# moondancer register map
Vendor: luna-soc
Registers are 8-bit, read-write, reset 0x0 unless marked. A register's access mark holds for its fields unless they carry their own. Offsets are from the block's base; [hi:lo] are bit positions; <NAME> marks a mode.

## timer0
Base 0xF0000500
Same registers: timer1 0xF0000600
0x00 enable — Counter enable
  [0] enable
0x01 mode — Timer mode. When ``periodic`` is set to 1 the counter will automatically be reset to the reload value.
  [0] periodic
0x04 reload 32-bit — Reload value of counter.
  [31:0] value
0x08 counter 32-bit — A CSR register. Parameters ---------- fields : :class:`dict` or :class:`list` or :class:`Field` Collection of register fields. If ``None`` (default), a dict is populated from Python :term:`variable annotations <python:variable annotations>`. ``fields`` is used to create a :class:`FieldActionMap`, :class:`FieldActionArray`, or :class:`FieldAction`, depending on its type (dict, list, or Field). Interface attributes -------------------- element : :class:`Element` Interface between this register and a CSR bus primitive. Attributes ---------- field : :class:`FieldActionMap` or :class:`FieldActionArray` or :class:`FieldAction` Collection of field instances. f : :class:`FieldActionMap` or :class:`FieldActionArray` or :class:`FieldAction` Shorthand for :attr:`Register.field`. Raises ------ :exc:`TypeError` If ``fields`` is neither ``None``, a :class:`dict`, a :class:`list`, or a :class:`Field`. :exc:`ValueError` If ``fields`` is not ``None`` and at least one variable annotation is a :class:`Field`. :exc:`ValueError` If ``element.access`` is not readable and at least one field is readable. :exc:`ValueError` If ``element.access`` is not writable and at least one field is writable.
  [31:0] value ro
0x10 ev_enable — A CSR register. Parameters ---------- fields : :class:`dict` or :class:`list` or :class:`Field` Collection of register fields. If ``None`` (default), a dict is populated from Python :term:`variable annotations <python:variable annotations>`. ``fields`` is used to create a :class:`FieldActionMap`, :class:`FieldActionArray`, or :class:`FieldAction`, depending on its type (dict, list, or Field). Interface attributes -------------------- element : :class:`Element` Interface between this register and a CSR bus primitive. Attributes ---------- field : :class:`FieldActionMap` or :class:`FieldActionArray` or :class:`FieldAction` Collection of field instances. f : :class:`FieldActionMap` or :class:`FieldActionArray` or :class:`FieldAction` Shorthand for :attr:`Register.field`. Raises ------ :exc:`TypeError` If ``fields`` is neither ``None``, a :class:`dict`, a :class:`list`, or a :class:`Field`. :exc:`ValueError` If ``fields`` is not ``None`` and at least one variable annotation is a :class:`Field`. :exc:`ValueError` If ``element.access`` is not readable and at least one field is readable. :exc:`ValueError` If ``element.access`` is not writable and at least one field is writable.
  [0] mask
0x11 ev_pending — A CSR register. Parameters ---------- fields : :class:`dict` or :class:`list` or :class:`Field` Collection of register fields. If ``None`` (default), a dict is populated from Python :term:`variable annotations <python:variable annotations>`. ``fields`` is used to create a :class:`FieldActionMap`, :class:`FieldActionArray`, or :class:`FieldAction`, depending on its type (dict, list, or Field). Interface attributes -------------------- element : :class:`Element` Interface between this register and a CSR bus primitive. Attributes ---------- field : :class:`FieldActionMap` or :class:`FieldActionArray` or :class:`FieldAction` Collection of field instances. f : :class:`FieldActionMap` or :class:`FieldActionArray` or :class:`FieldAction` Shorthand for :attr:`Register.field`. Raises ------ :exc:`TypeError` If ``fields`` is neither ``None``, a :class:`dict`, a :class:`list`, or a :class:`Field`. :exc:`ValueError` If ``fields`` is not ``None`` and at least one variable annotation is a :class:`Field`. :exc:`ValueError` If ``element.access`` is not readable and at least one field is readable. :exc:`ValueError` If ``element.access`` is not writable and at least one field is writable.
  [0] mask

## usb0_ep_control
Base 0xF0000900
Same registers: usb1_ep_control 0xF0000D00, usb2_ep_control 0xF0001100
Registers as timer0, without enable, mode, reload, counter; these are added or differ:
0x00 control — Control register address: Controls the current device's USB address. Should be written after a SET_ADDRESS request is received. Automatically resets back to zero on a USB reset.
  [7:0] address wo
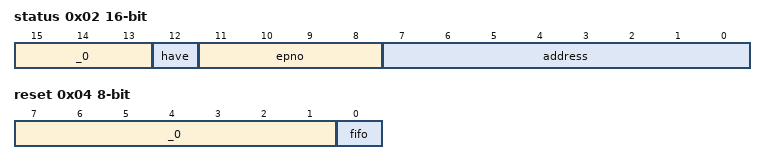
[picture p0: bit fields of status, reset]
0x02 status 16-bit — Status register address: Holds the current device's active USB address. epno: The endpoint number associated with the most recently captured SETUP packet. have: `1` iff data is available in the FIFO.
  [15:13] _0, [12] have ro, [11:8] epno ro, [7:0] address ro
0x04 reset — Reset register fifo: Local reset control for the SETUP handler; writing a '1' to this register clears the handler state.
  [7:1] _0, [0] fifo wo
0x05 data — Data register A FIFO that returns the bytes from the most recently captured SETUP packet. Reading a byte from this register advances the FIFO. The first eight bytes read from this contain the core SETUP packet.
  [7:0] byte ro

## usb0_ep_in
Base 0xF0000A00
Same registers: usb1_ep_in 0xF0000E00, usb2_ep_in 0xF0001200
Registers as timer0, without enable, mode, reload, counter; these are added or differ:
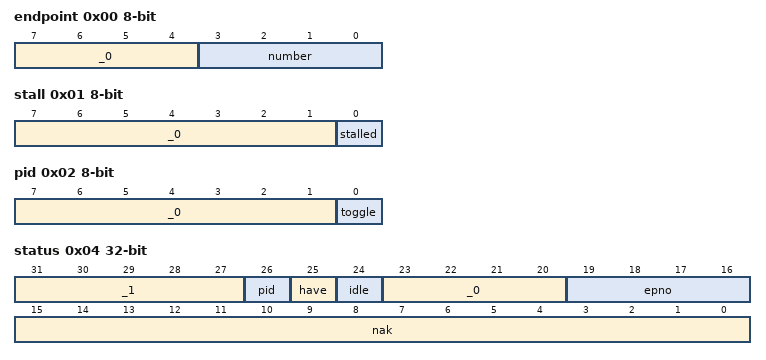
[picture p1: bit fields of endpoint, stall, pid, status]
0x00 endpoint — Endpoint register number: Contains the endpoint the enqueued packet is to be transmitted on. Writing to this field marks the relevant packet as ready to transmit; and thus should only be written after a full packet has been written into the FIFO. If no data has been placed into the DATA FIFO, a zero-length packet is generated. Note that any IN requests that do not match the endpoint number are automatically NAK'd.
  [7:4] _0, [3:0] number wo
0x01 stall — Stall register stalled: When this field contains '1', any IN tokens targeting `epno` will be responded to with a STALL token, rather than DATA or a NAK. For EP0, this field will automatically be cleared when a new SETUP token is received.
  [7:1] _0, [0] stalled wo
0x02 pid — Pid register toggle: Sets the current PID toggle bit for the given endpoint.
  [7:1] _0, [0] toggle wo
0x04 status 32-bit — Status register nak: Contains a bitmask of endpoints that have responded with a NAK since the last read of this register. epno: Contains the endpoint being transmitted on. idle: This value is `1` if no packet is actively being transmitted. have: This value is `1` if data is present in the transmit FIFO. pid: Contains the current PID toggle bit for the given endpoint.
  [31:27] _1, [26] pid ro, [25] have ro, [24] idle ro, [23:20] _0, [19:16] epno ro, [15:0] nak ro
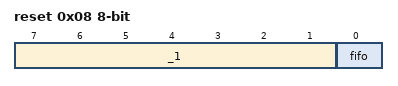
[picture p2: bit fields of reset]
0x08 reset — Reset register fifo: A write to this field Clears the FIFO without transmitting.
  [7:1] _1, [0] fifo wo
0x09 data — Data register Each write enqueues a byte to be transmitted; gradually building a single packet to be transmitted. This queue should only ever contain a single packet; it is the software's responsibility to handle breaking requests down into packets.
  [7:0] byte wo
